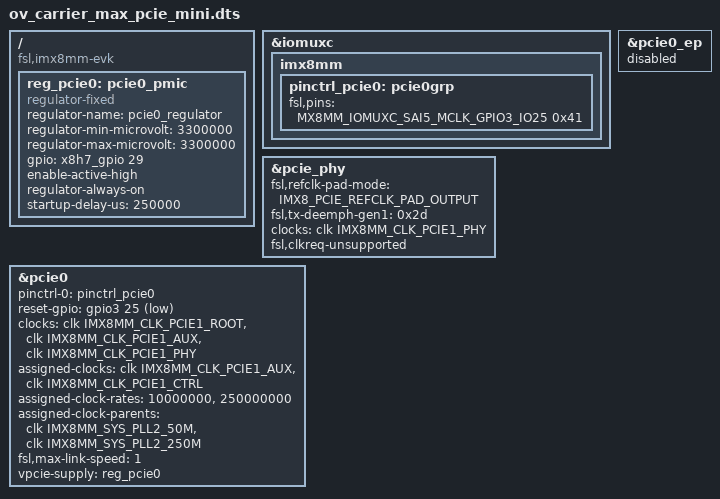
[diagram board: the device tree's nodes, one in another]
/**
 * Portenta-X8 dtb overlay file
 * Arduino 2021
 * Enable pcie mini connector on Arduino Max carrier board
 * NOTES:
 * - CLKREQ# unsupported. Should be de-asserted by pcie device to signal stand-by operation
 * - W_DISABLE# unsupported. Should be driven by Portenta-X8 to shutdown RF operation of pcie device
 */

/dts-v1/;
/plugin/;

#include "imx8mm-pinfunc.h"
#include <dt-bindings/phy/phy-imx8-pcie.h>
#include <dt-bindings/clock/imx8mm-clock.h>
#include <dt-bindings/gpio/gpio.h>

/ {
	compatible = "fsl,imx8mm-evk", "fsl,imx8mm";

	fragment@0 {
		target = <&iomuxc>;
		__overlay__ {
			imx8mm {
				pinctrl_pcie0: pcie0grp {
					fsl,pins = <
						MX8MM_IOMUXC_SAI5_MCLK_GPIO3_IO25		0x41  /* PCIE_nRST */
						/* PCIE_CLKREQ should be input, pull down, PWM9 stm32h7 PC8 */
						/* PCIE_W_DISABLE, should be output, open drain, A1 stm32h7 PA6 */
					>;
				};
			};
		};
	};

	fragment@1 {
		target-path = "/";
		__overlay__ {
			reg_pcie0: pcie0_pmic {
				compatible = "regulator-fixed";
				regulator-name = "pcie0_regulator";
				regulator-min-microvolt = <3300000>;
				regulator-max-microvolt = <3300000>;
				gpio = <&x8h7_gpio 29 GPIO_ACTIVE_HIGH>; /* stm32h7 PWM6 */
				enable-active-high;
				regulator-always-on;
				startup-delay-us = <250000>;
			};
		};
	};

	fragment@2 {
		target = <&pcie_phy>;
		__overlay__ {
			fsl,refclk-pad-mode = <IMX8_PCIE_REFCLK_PAD_OUTPUT>;
			fsl,tx-deemph-gen1 = <0x2d>;
			/*fsl,tx-deemph-gen2 = <0xf>;*/
			clocks = <&clk IMX8MM_CLK_PCIE1_PHY>;
			fsl,clkreq-unsupported;
			status = "okay";
		};
	};

	fragment@3 {
		target = <&pcie0>;
		__overlay__ {
			pinctrl-names = "default";
			pinctrl-0 = <&pinctrl_pcie0>;
			reset-gpio = <&gpio3 25 GPIO_ACTIVE_LOW>;
			clocks = <&clk IMX8MM_CLK_PCIE1_ROOT>, <&clk IMX8MM_CLK_PCIE1_AUX>,
				 <&clk IMX8MM_CLK_PCIE1_PHY>;
			clock-names = "pcie", "pcie_aux", "pcie_bus";
			assigned-clocks = <&clk IMX8MM_CLK_PCIE1_AUX>,
					  <&clk IMX8MM_CLK_PCIE1_CTRL>;
			assigned-clock-rates = <10000000>, <250000000>;
			assigned-clock-parents = <&clk IMX8MM_SYS_PLL2_50M>,
						 <&clk IMX8MM_SYS_PLL2_250M>;
			fsl,max-link-speed = <1>;
			vpcie-supply = <&reg_pcie0>;
			status = "okay";
		};
	};

	fragment@4 {
		target = <&pcie0_ep>;
		__overlay__ {
			status = "disabled";
		};
	};
};
